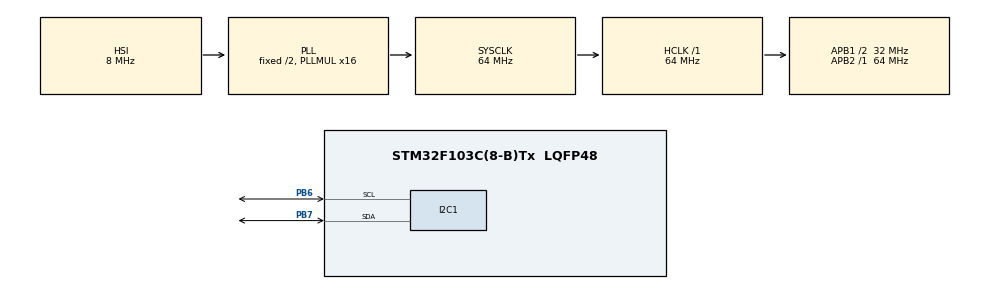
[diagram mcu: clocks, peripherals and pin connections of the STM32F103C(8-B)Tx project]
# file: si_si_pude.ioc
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Mcu.Family=STM32F1
Mcu.Name=STM32F103C(8-B)Tx
Mcu.Package=LQFP48
NVIC.PriorityGroup=NVIC_PRIORITYGROUP_4
PB6.Mode=I2C
PB6.Signal=I2C1_SCL
PB7.Mode=I2C
PB7.Signal=I2C1_SDA
ProjectManager.HeapSize=0x200
ProjectManager.StackSize=0x400
ProjectManager.TargetToolchain=STM32CubeIDE
RCC.AHBFreq_Value=64000000
RCC.APB1CLKDivider=RCC_HCLK_DIV2
RCC.APB1Freq_Value=32000000
RCC.APB1TimFreq_Value=64000000
RCC.APB2Freq_Value=64000000
RCC.APB2TimFreq_Value=64000000
RCC.HCLKFreq_Value=64000000
RCC.PLLMUL=RCC_PLL_MUL16
RCC.SYSCLKFreq_VALUE=64000000
RCC.SYSCLKSource=RCC_SYSCLKSOURCE_PLLCLK
RCC.USBFreq_Value=64000000
board=custom

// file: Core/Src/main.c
/* USER CODE BEGIN Header */
/**
  ******************************************************************************
  * @file           : main.c
  * @brief          : Main program body
  ******************************************************************************
  * @attention
  *
  * Copyright (c) 2023 STMicroelectronics.
  * All rights reserved.
  *
  * This software is licensed under terms that can be found in the LICENSE file
  * in the root directory of this software component.
  * If no LICENSE file comes with this software, it is provided AS-IS.
  *
  ******************************************************************************
  */
/* USER CODE END Header */
#include "main.h"

I2C_HandleTypeDef hi2c1;

void SystemClock_Config(void);
static void MX_GPIO_Init(void);
static void MX_I2C1_Init(void);

/* USER CODE BEGIN 0 */
void pca9685_init(I2C_HandleTypeDef *hi2c, uint8_t address)
{
#define PCA9685_MODE1 0x00
uint8_t initStruct[2];
uint8_t prescale = 0x144; // hardcoded
HAL_I2C_Master_Transmit(hi2c, address, PCA9685_MODE1, 1, 1);
uint8_t oldmode = 0; // hardcoded
// HAL_I2C_Master_Receive(hi2c, address, &oldmode, 1, 1);
uint8_t newmode = ((oldmode & 0x7F) | 0x10);
initStruct[0] = PCA9685_MODE1;
initStruct[1] = newmode;
HAL_I2C_Master_Transmit(hi2c, address, initStruct, 2, 1);
initStruct[1] = prescale;
HAL_I2C_Master_Transmit(hi2c, address, initStruct, 2, 1);
initStruct[1] = oldmode;
HAL_I2C_Master_Transmit(hi2c, address, initStruct, 2, 1);
HAL_Delay(5);
initStruct[1] = (oldmode | 0xA1);
HAL_I2C_Master_Transmit(hi2c, address, initStruct, 2, 1);
}

void pca9685_pwm(I2C_HandleTypeDef *hi2c, uint8_t address, uint8_t num, uint16_t on, uint16_t off)
{
uint8_t outputBuffer[5] = {0x06 + 4*num, on, (on >> 8), off, (off >> 8)};
HAL_I2C_Master_Transmit(&hi2c1, address, outputBuffer, 5, 1);
}
/* USER CODE END 0 */

int main(void)
{

  /* MCU Configuration--------------------------------------------------------*/

  /* Reset of all peripherals, Initializes the Flash interface and the Systick. */
  HAL_Init();

  /* Configure the system clock */
  SystemClock_Config();

  /* Initialize all configured peripherals */
  MX_GPIO_Init();
  MX_I2C1_Init();
  /* USER CODE BEGIN 2 */
  pca9685_init(&hi2c1, 0x80);
  /* USER CODE END 2 */

  /* Infinite loop */
  /* USER CODE BEGIN WHILE */
  int i=0;
  int up=10;
  //HAL_Delay(5000);
  while (1)
  {
    /* USER CODE END WHILE */

    /* USER CODE BEGIN 3 */
	 /*i=1000;
	  pca9685_pwm(&hi2c1, 0x80, 0, 0, 1850); // legs down-up: 1200-1850
	  pca9685_pwm(&hi2c1, 0x80, 1, 0, 1850);
	  pca9685_pwm(&hi2c1, 0x80, 2, 0, 1000); //folding down-up: 1850-1000
	  pca9685_pwm(&hi2c1, 0x80, 3, 0, 0);
	  HAL_Delay(1000);

	  i=1850;
	  pca9685_pwm(&hi2c1, 0x80, 0, 0, 1200);
	  pca9685_pwm(&hi2c1, 0x80, 1, 0, 1200);
	  pca9685_pwm(&hi2c1, 0x80, 2, 0, 1850);
	  pca9685_pwm(&hi2c1, 0x80, 3, 0, i);
	  HAL_Delay(1000);

	  i = i+up;

	  if(i<150){ //from 105 we start to see movement
		  i = i+up;
	  	  }

	  	  if(i<1200||i>1850){
		  up = up*-1;
	  }
	  i = i+up;

	  */
	  /*int count = 0;
	  while(count<5){
		  pca9685_pwm(&hi2c1, 0x80, 0, 0, i);
		  pca9685_pwm(&hi2c1, 0x80, 1, 0, i);
		  pca9685_pwm(&hi2c1, 0x80, 2, 0, i);
		  HAL_Delay(1);
		  if(i<1000||i>1850){
		  up = up*-1;
		  count = count + 1;
		  }
		   i = i+up;
	  }
	  pca9685_pwm(&hi2c1, 0x80, 0, 0, 0);
	  pca9685_pwm(&hi2c1, 0x80, 1, 0, 0);
	  pca9685_pwm(&hi2c1, 0x80, 2, 0, 0);
	  HAL_Delay(1000)

	  i = 0;
	  pca9685_pwm(&hi2c1, 0x80, 0, 0, 0);
	  pca9685_pwm(&hi2c1, 0x80, 1, 0, 0);
	  pca9685_pwm(&hi2c1, 0x80, 2, 0, 0);
	  while (i<600){
		  pca9685_pwm(&hi2c1, 0x80, 3, 0, i);
		  i = i+up;
		  HAL_Delay(1);
	  }

	   pca9685_pwm(&hi2c1, 0x80, 4, 0, i);
	  HAL_Delay(1);
	  if(i<1150||i>1450){
	  up = up*-1;
	  }
	  i = i+up;
	  HAL_Delay(5000);
	  pca9685_pwm(&hi2c1, 0x80, 3, 0, 0);
	  HAL_Delay(5000);
	  while (i<1800){
		  pca9685_pwm(&hi2c1, 0x80, 3, 0, i);
		  i = i+up;
		  HAL_Delay(1);
	  }
	  HAL_Delay(5000);
	  while (i>0){
		  pca9685_pwm(&hi2c1, 0x80, 3, 0, i);
		  i = i-up;
		  HAL_Delay(1);
	  }
	  pca9685_pwm(&hi2c1, 0x80, 4, 0, 1150);
	  HAL_Delay(1000);
	  pca9685_pwm(&hi2c1, 0x80, 4, 0, 0);
	  HAL_Delay(1000);

	  while (i<800){
		  pca9685_pwm(&hi2c1, 0x80, 3, 0, i);
		  i = i+up;
		  HAL_Delay(1);
	  }
	  HAL_Delay(1000);
	  while (i>0){
		  pca9685_pwm(&hi2c1, 0x80, 3, 0, i);
		  i = i-up;
		  HAL_Delay(1);
	  }
	  pca9685_pwm(&hi2c1, 0x80, 4, 0, 1450);
	  HAL_Delay(1000);*/

	  HAL_Delay(500);
	  while (i<1800){
		  pca9685_pwm(&hi2c1, 0x80, 3, 0, i);
		  i = i+up;
		  HAL_Delay(1);
	  }
	  HAL_Delay(500);
	  while (i>0){
		  pca9685_pwm(&hi2c1, 0x80, 3, 0, i);
		  i = i-up;
		  HAL_Delay(1);
	  }

  }
  /* USER CODE END 3 */
}

void SystemClock_Config(void)
{
  RCC_OscInitTypeDef RCC_OscInitStruct = {0};
  RCC_ClkInitTypeDef RCC_ClkInitStruct = {0};

  /** Initializes the RCC Oscillators according to the specified parameters
  * in the RCC_OscInitTypeDef structure.
  */
  RCC_OscInitStruct.OscillatorType = RCC_OSCILLATORTYPE_HSI;
  RCC_OscInitStruct.HSIState = RCC_HSI_ON;
  RCC_OscInitStruct.HSICalibrationValue = RCC_HSICALIBRATION_DEFAULT;
  RCC_OscInitStruct.PLL.PLLState = RCC_PLL_ON;
  RCC_OscInitStruct.PLL.PLLSource = RCC_PLLSOURCE_HSI_DIV2;
  RCC_OscInitStruct.PLL.PLLMUL = RCC_PLL_MUL16;
  if (HAL_RCC_OscConfig(&RCC_OscInitStruct) != HAL_OK)
  {
    Error_Handler();
  }

  /** Initializes the CPU, AHB and APB buses clocks
  */
  RCC_ClkInitStruct.ClockType = RCC_CLOCKTYPE_HCLK|RCC_CLOCKTYPE_SYSCLK
                              |RCC_CLOCKTYPE_PCLK1|RCC_CLOCKTYPE_PCLK2;
  RCC_ClkInitStruct.SYSCLKSource = RCC_SYSCLKSOURCE_PLLCLK;
  RCC_ClkInitStruct.AHBCLKDivider = RCC_SYSCLK_DIV1;
  RCC_ClkInitStruct.APB1CLKDivider = RCC_HCLK_DIV2;
  RCC_ClkInitStruct.APB2CLKDivider = RCC_HCLK_DIV1;

  if (HAL_RCC_ClockConfig(&RCC_ClkInitStruct, FLASH_LATENCY_2) != HAL_OK)
  {
    Error_Handler();
  }
}

static void MX_I2C1_Init(void)
{

  hi2c1.Instance = I2C1;
  hi2c1.Init.ClockSpeed = 100000;
  hi2c1.Init.DutyCycle = I2C_DUTYCYCLE_2;
  hi2c1.Init.OwnAddress1 = 0;
  hi2c1.Init.AddressingMode = I2C_ADDRESSINGMODE_7BIT;
  hi2c1.Init.DualAddressMode = I2C_DUALADDRESS_DISABLE;
  hi2c1.Init.OwnAddress2 = 0;
  hi2c1.Init.GeneralCallMode = I2C_GENERALCALL_DISABLE;
  hi2c1.Init.NoStretchMode = I2C_NOSTRETCH_DISABLE;
  if (HAL_I2C_Init(&hi2c1) != HAL_OK)
  {
    Error_Handler();
  }

}

static void MX_GPIO_Init(void)
{
  GPIO_InitTypeDef GPIO_InitStruct = {0};

  /* GPIO Ports Clock Enable */
  __HAL_RCC_GPIOB_CLK_ENABLE();

  /*Configure GPIO pin Output Level */
  HAL_GPIO_WritePin(GPIOB, GPIO_PIN_9, GPIO_PIN_RESET);

  /*Configure GPIO pin : PB9 */
  GPIO_InitStruct.Pin = GPIO_PIN_9;
  GPIO_InitStruct.Mode = GPIO_MODE_OUTPUT_PP;
  GPIO_InitStruct.Pull = GPIO_NOPULL;
  GPIO_InitStruct.Speed = GPIO_SPEED_FREQ_LOW;
  HAL_GPIO_Init(GPIOB, &GPIO_InitStruct);

}

void Error_Handler(void)
{
  __disable_irq();
  while (1)
  {
  }
}
